# WKUP_IA_CORE register map
Vendor: Texas Instruments
Peripheral module from a debugger description file (folder omap34xx).
Registers are 32-bit, read-only, reset 0x0 unless marked. A register's access mark holds for its fields unless they carry their own. Offsets are as the file gives them; lines under a group give offsets from that group; [hi:lo] are bit positions; {n}, {i} and the like mark numbered series; 'fields as' and 'values as' point back to an identical list; <NAME> marks a mode.

## WKUP_IA_CORE
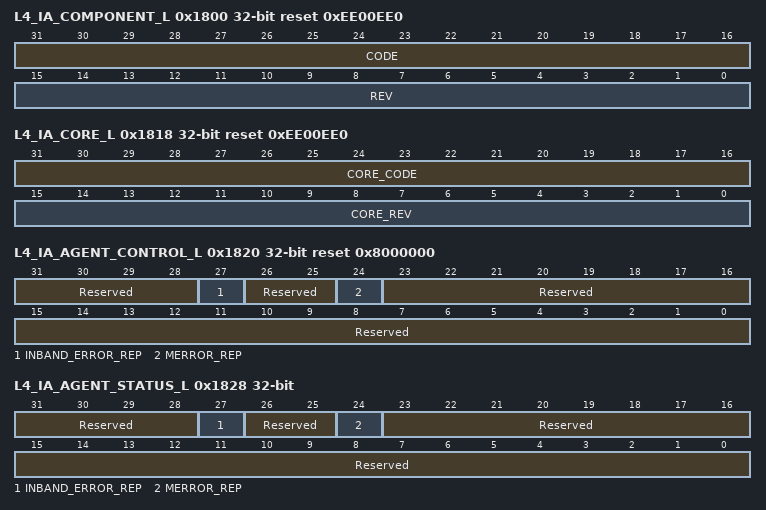
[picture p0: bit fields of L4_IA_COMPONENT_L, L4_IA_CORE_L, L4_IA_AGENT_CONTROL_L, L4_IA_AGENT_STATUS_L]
0x1800 L4_IA_COMPONENT_L reset 0xEE00EE0 — COMPONENT register identifies the component to which this register block belongs. The register contains a component code and revision, which are used to identify the hardware of the component. The COMPONENT register is read-only.
  [31:16] CODE — Interconnect code
  [15:0] REV — Component revision code
0x1804 L4_IA_COMPONENT_H reset 0xEE0 — COMPONENT register identifies the component to which this register block belongs. The register contains a component code and revision, which are used to identify the hardware of the component. The COMPONENT register is read-only.
  [15:0] VENDOR_CODE — Vendor revision code
0x1818 L4_IA_CORE_L reset 0xEE00EE0 — Provide information about the core initiator
  [31:16] CORE_CODE — Interconnect core code
  [15:0] CORE_REV — Component revision code code
0x181C L4_IA_CORE_H reset 0xEE0 — Provide information about the core initiator
  [15:0] VENDOR_CODE — Vendor revision core code
0x1820 L4_IA_AGENT_CONTROL_L reset 0x8000000 — Enable error reporting on an initiator interface.The error reporting mechanism is enabled when the INBAND_ERROR_REP bit field is set to 1. The out-of-band OCP MError reporting mechanism is enabled when the MERROR_REP bit field is set to 1.
  [31:28] Reserved — Read returns 0.
  [27] INBAND_ERROR_REP — Setting this field to 1 reports on in-band errors using the INBAND_ERROR log bit of IA.AGENT_STATUS register.
  [26:25] Reserved — Read returns 0.
  [24] MERROR_REP — Enable MError reporting
  [23:0] Reserved — Read returns 0.
0x1824 L4_IA_AGENT_CONTROL_H — Enable error reporting on an initiator interface.
  [31:0] Reserved — Read returns 0.
0x1828 L4_IA_AGENT_STATUS_L access not given — Stores status information for an initiator. The INBAND_ERROR and MERROR fields are read/write and are implemented as log bits.
  [31:28] Reserved ro — Read returns 0.
  [27] INBAND_ERROR_REP — 0x0 No In-Band error present.0x1 In-Band error present. (access R 1toClr)
  [26:25] Reserved ro — Read returns 0.
  [24] MERROR_REP ro — 0x0 No MError error present.0x1 MErorr error present.
  [23:0] Reserved ro — Read returns 0.
0x182C L4_IA_AGENT_STATUS_H — Stores status information for an initiator.
  [31:0] Reserved — Read returns 0.
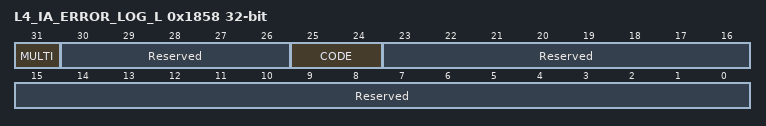
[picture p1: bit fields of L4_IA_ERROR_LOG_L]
0x1858 L4_IA_ERROR_LOG_L access per field — Log information about error conditions. The CODE field logs any protection violation or address hole errors detected by the initiator subsystem while decoding a request.
  [31] MULTI rw — While the CODE field is not zero, the MULTI bit is asserted whenever an additional error is detected. Once set by hardware, the MULTI bit can only be cleared by writing a 1 to it while writing a value other than zero to the CODE field.
  [30:26] Reserved ro — Read returns 0.
  [25:24] CODE rw — The error code of an initiator request.0x00: No errors0x01: Reserved0x10: Address hole0x11: Protection violationThe CODE field, once set by hardware, can only be cleared by writing a non-zero value to it, in conjunction with writing a 1 to the MULTI bit field.
  [23:0] Reserved ro — Read returns 0.
0x185C L4_IA_ERROR_LOG_H — Log information about error conditions.
  [31:0] Reserved — Read returns 0.
